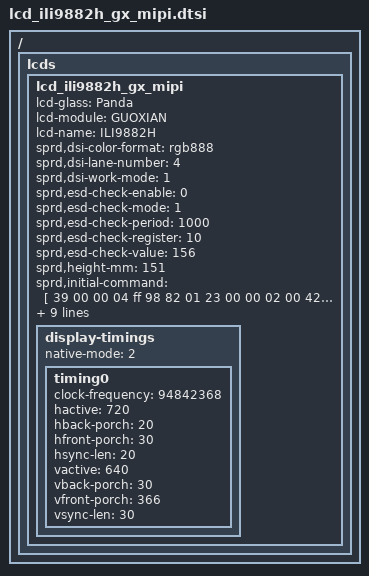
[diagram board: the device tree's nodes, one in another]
/ {
	fragment {
		target-path = "/";
		__overlay__ {
			lcds {
				lcd_ili9882h_gx_mipi: lcd_ili9882h_gx_mipi {
					lcd-glass = "Panda";
					lcd-module = "GUOXIAN";
					lcd-name = "ILI9882H";
					sprd,dsi-color-format = "rgb888";
					sprd,dsi-lane-number = <4>;
					sprd,dsi-work-mode = <1>;
					
					sprd,esd-check-enable = <0>;
					sprd,esd-check-mode = <1>;
					sprd,esd-check-period = <1000>;
					sprd,esd-check-register = <10>;
					sprd,esd-check-value = <156>;
					sprd,height-mm = <151>;
					sprd,initial-command = [
						39 00 00 04 ff 98 82 01
						23 00 00 02 00 42 23 00
						00 02 01 33 23 00 00 02
						02 01 23 00 00 02 03 00
						23 00 00 02 04 02 23 00
						00 02 05 31 23 00 00 02
						07 00 23 00 00 02 08 80
						23 00 00 02 09 81 23 00
						00 02 0a 71 23 00 00 02
						0b 00 23 00 00 02 0c 01
						23 00 00 02 0d 01 23 00
						00 02 0e 00 23 00 00 02
						0f 00 23 00 00 02 28 88
						23 00 00 02 29 88 23 00
						00 02 2a 00 23 00 00 02
						2b 00 23 00 00 02 31 07
						23 00 00 02 32 0c 23 00
						00 02 33 22 23 00 00 02
						34 23 23 00 00 02 35 07
						23 00 00 02 36 08 23 00
						00 02 37 16 23 00 00 02
						38 14 23 00 00 02 39 12
						23 00 00 02 3a 10 23 00
						00 02 3b 21 23 00 00 02
						3c 07 23 00 00 02 3d 07
						23 00 00 02 3e 07 23 00
						00 02 3f 07 23 00 00 02
						40 07 23 00 00 02 41 07
						23 00 00 02 42 07 23 00
						00 02 43 07 23 00 00 02
						44 07 23 00 00 02 45 07
						23 00 00 02 46 07 23 00
						00 02 47 07 23 00 00 02
						48 0d 23 00 00 02 49 22
						23 00 00 02 4a 23 23 00
						00 02 4b 07 23 00 00 02
						4c 09 23 00 00 02 4d 17
						23 00 00 02 4e 15 23 00
						00 02 4f 13 23 00 00 02
						50 11 23 00 00 02 51 21
						23 00 00 02 52 07 23 00
						00 02 53 07 23 00 00 02
						54 07 23 00 00 02 55 07
						23 00 00 02 56 07 23 00
						00 02 57 07 23 00 00 02
						58 07 23 00 00 02 59 07
						23 00 00 02 5a 07 23 00
						00 02 5b 07 23 00 00 02
						5c 07 23 00 00 02 61 07
						23 00 00 02 62 0d 23 00
						00 02 63 22 23 00 00 02
						64 23 23 00 00 02 65 07
						23 00 00 02 66 09 23 00
						00 02 67 11 23 00 00 02
						68 13 23 00 00 02 69 15
						23 00 00 02 6a 17 23 00
						00 02 6b 21 23 00 00 02
						6c 07 23 00 00 02 6d 07
						23 00 00 02 6e 07 23 00
						00 02 6f 07 23 00 00 02
						70 07 23 00 00 02 71 07
						23 00 00 02 72 07 23 00
						00 02 73 07 23 00 00 02
						74 07 23 00 00 02 75 07
						23 00 00 02 76 07 23 00
						00 02 77 07 23 00 00 02
						78 0c 23 00 00 02 79 22
						23 00 00 02 7a 23 23 00
						00 02 7b 07 23 00 00 02
						7c 08 23 00 00 02 7d 10
						23 00 00 02 7e 12 23 00
						00 02 7f 14 23 00 00 02
						80 16 23 00 00 02 81 21
						23 00 00 02 82 07 23 00
						00 02 83 07 23 00 00 02
						84 07 23 00 00 02 85 07
						23 00 00 02 86 07 23 00
						00 02 87 07 23 00 00 02
						88 07 23 00 00 02 89 07
						23 00 00 02 8a 07 23 00
						00 02 8b 07 23 00 00 02
						8c 07 23 00 00 02 b0 33
						23 00 00 02 ba 06 23 00
						00 02 c0 07 23 00 00 02
						c1 00 23 00 00 02 c2 00
						23 00 00 02 c3 00 23 00
						00 02 c4 00 23 00 00 02
						ca 44 23 00 00 02 d0 01
						23 00 00 02 d1 22 23 00
						00 02 d3 40 23 00 00 02
						d5 51 23 00 00 02 d6 20
						23 00 00 02 d7 01 23 00
						00 02 d8 00 23 00 00 02
						dc c2 23 00 00 02 dd 10
						23 00 00 02 df b6 23 00
						00 02 e0 3e 23 00 00 02
						e2 47 23 00 00 02 e7 54
						23 00 00 02 e6 22 23 00
						00 02 ee 15 23 00 00 02
						f1 00 23 00 00 02 f2 00
						23 00 00 02 fa df 39 00
						00 04 ff 98 82 02 23 00
						00 02 f1 1c 23 00 00 02
						40 4b 23 00 00 02 4b 5a
						23 00 00 02 50 ca 23 00
						00 02 51 50 23 00 00 02
						06 8d 23 00 00 02 0b a0
						23 00 00 02 0c 80 23 00
						00 02 0d 1a 23 00 00 02
						0e 04 23 00 00 02 4d ce
						23 00 00 02 73 04 23 00
						00 02 70 32 39 00 00 04
						ff 98 82 05 23 00 00 02
						a8 62 23 00 00 02 63 73
						23 00 00 02 64 73 23 00
						00 02 68 65 23 00 00 02
						69 6b 23 00 00 02 6a a1
						23 00 00 02 6b 93 23 00
						00 02 00 01 23 00 00 02
						46 00 23 00 00 02 45 01
						23 00 00 02 17 50 23 00
						00 02 18 01 23 00 00 02
						85 37 23 00 00 02 86 0f
						39 00 00 04 ff 98 82 06
						23 00 00 02 d9 1f 23 00
						00 02 c0 40 23 00 00 02
						c1 16 23 00 00 02 07 f7
						39 00 00 04 ff 98 82 08
						39 00 00 1c e0 40 24 98
						d1 10 55 40 64 8d ad a9
						de 04 25 45 aa 66 90 ac
						d3 fe f6 26 65 9e 03 ec
						39 00 00 1c e1 40 24 98
						d1 10 55 40 64 8d ad a9
						de 04 25 45 aa 66 90 ac
						d3 fe f6 26 65 9e 03 ec
						39 00 00 04 ff 98 82 0b
						23 00 00 02 9a 44 23 00
						00 02 9b 88 23 00 00 02
						9c 03 23 00 00 02 9d 03
						23 00 00 02 9e 71 23 00
						00 02 9f 71 23 00 00 02
						ab e0 39 00 00 04 ff 98
						82 0e 23 00 00 02 02 09
						23 00 00 02 11 50 23 00
						00 02 13 10 23 00 00 02
						00 a0 39 00 00 04 ff 98
						82 00 23 78 00 02 11 00
						23 14 00 02 29 00
					];
					sprd,phy-bit-clock = <729856>;
					sprd,phy-escape-clock = <20000>;
					sprd,reset-on-sequence = <1 10 0 10 1 20>;
					sprd,sleep-in-command = <600502272 673791504 1376256>;
					sprd,sleep-out-command = [23 96 00 02 11 00 23 1e 00 02 29 00 23 00 00 02 35 00];
					sprd,use-dcs-write;
					sprd,width-mm = <68>;

					display-timings {
						native-mode = <2>;

						timing0 {
							clock-frequency = <94842368>;
							hactive = <720>;
							hback-porch = <20>;
							hfront-porch = <30>;
							hsync-len = <20>;
							vactive = <640>;
							vback-porch = <30>;
							vfront-porch = <366>;
							vsync-len = <30>;
						};
					};
				};
			};
		};
	};
};

